# dm646x_cslr_uart register map
Vendor: Texas Instruments
Peripheral module from a debugger description file.
Registers are 32-bit, access not given, reset 0x0 unless marked. A register's access mark holds for its fields unless they carry their own. Offsets are as the file gives them; lines under a group give offsets from that group; [hi:lo] are bit positions; {n}, {i} and the like mark numbered series; 'fields as' and 'values as' point back to an identical list; <NAME> marks a mode.

## UART — UART/IrDA/CIR
0x00 RHR — Receive Holding Register
  [7:0] RHR ro
0x00 THR — Transmit Holding Register
  [7:0] THR wo
0x00 DLL — Divisor Latches Low
  [7:0] CLOCK_LSB rw — LSB divisor value
0x04 IER — Interrupt Enable Register
  [7] CTS_IT rw — UART MODE ONLY, 0 disables CTS interrupt
  [7] EOF_IT rw — IRDA MODE ONLY, 0 disables received EOF interrupt
  [6] LINE_STS_IT_IRDA rw — IRDA MODE ONLY, 0 disables receiver line status interrupt
  [6] RTS_IT rw — UART MODE ONLY, 0 disables RTS interrupt
  [5] XOFF_IT rw — UART MODE ONLY, 0 disables XOFF interrupt
  [5] TX_STATUS_IT rw — IRDA and CIR MODE ONLY, 0 disables TX status interrupt
  [4] STS_FIFO_TRIG_IT rw — IRDA MODE ONLY, 0 disables FIFO trigger level interrupt
  [4] SLEEP_MODE rw — UART MODE ONLY, 0 disables sleep mode
  [3] MODEM_STS_IT rw — UART MODE ONLY, 0 disables modem status interrupt
  [3] RX_OVERRUN_IT rw — IRDA and CIR MODE ONLY, 0 disables RX overrun interrupt
  [2] LAST_RX_BYTE_IT rw — IRDA MODE ONLY, 0 disables last byte of frame in RX FIFO interrupt
  [2] LINE_STS_IT_UART rw — UART MODE ONLY, 0 disables receiver line status interrupt
  [2] RX_STOP_IT rw — CIR MODE ONLY, 0 disables receive stop interrupt
  [1] THR_IT rw — 0 disables THR interrupt
  [0] RHR_IT rw — 0 disables RHR interrupt
0x04 DLH — Divisor Latches High
  [5:0] CLOCK_MSB rw — MSB divisor value
0x08 IIR reset 0x1 — Interrupt Identification Register
  [7] EOF_IT ro — IRDA MODE ONLY, 1 means received EOF interrupt active
  [7:6] FCR_MIRROR ro — UART MODE ONLY, Mirror the contents of FCR[0] on both bits
  [6] LINE_STS_IT ro — IRDA MODE ONLY, 1 means receiver line status interrupt active
  [5] TX_STATUS_IT ro — IRDA and CIR MODE ONLY, 1 means TX status interrupt active
  [4] STS_FIFO_IT ro — IRDA MODE ONLY, 1 means status FIFO trigger level interrupt active
  [3] RX_OE_IT ro — IRDA and CIR MODE ONLY, 1 means RX overrun interrupt active
  [2] RX_FIFO_LAST_BYTE_IT ro — IRDA MODE ONLY, 1 means last byte of frame in RX FIFO interrupt active
  [2] RX_STOP_IT ro — CIR MODE ONLY, 1 means receive stop interrupt active
  [5:1] IT_TYPE ro — UART MODE ONLY, Interrupt type identification
  [1] THR_IT ro — IRDA and CIR MODE ONLY, 1 means active THR interrupt
  [0] IT_PENDING ro — UART MODE ONLY, 1 means no pending interrupt
  [0] RHR_IT ro — IRDA and CIR MODE ONLY, 1 means active RHR interrupt
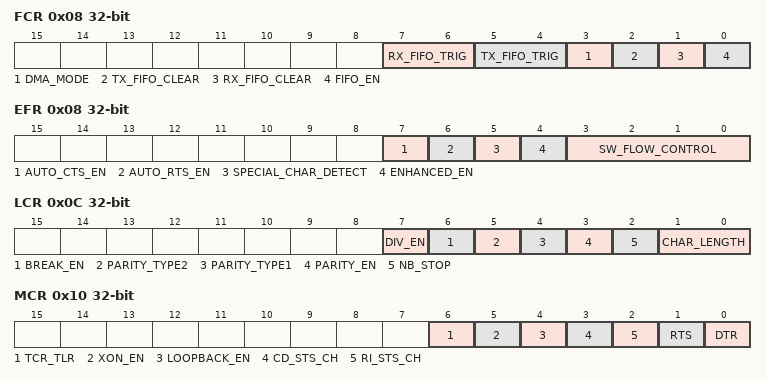
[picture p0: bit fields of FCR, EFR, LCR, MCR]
0x08 FCR — FIFO Control Register
  [7:6] RX_FIFO_TRIG wo — Set trigger elvel for RX FIFO
  [5:4] TX_FIFO_TRIG wo — Set trigger level for TX FIFO
  [3] DMA_MODE wo — 1 means DMA mode 1, 0 means no DMA
  [2] TX_FIFO_CLEAR wo — 1 clears transmit FIFO
  [1] RX_FIFO_CLEAR wo — 1 clears receive FIFO
  [0] FIFO_EN wo — 1 enables FIFO
0x08 EFR — Enhanced Feature Register
  [7] AUTO_CTS_EN rw — Auto-CTS enable
  [6] AUTO_RTS_EN rw — Auto-RTS enable
  [5] SPECIAL_CHAR_DETECT rw — Special character detect enable
  [4] ENHANCED_EN rw — Enhanced functions write enable bit
  [3:0] SW_FLOW_CONTROL rw — Defines software flow control
0x0C LCR — Line Control Register
  [7] DIV_EN rw — 1 enables divisor latch
  [6] BREAK_EN rw — Break control bit
  [5] PARITY_TYPE2 rw — Select forced parity format
  [4] PARITY_TYPE1 rw — 0->odd parity; 1->even parity
  [3] PARITY_EN rw — Enable parity bit generation
  [2] NB_STOP rw — Specifies number of stop bits
  [1:0] CHAR_LENGTH rw — Specifies word length
0x10 MCR — Modem Control Register
  [6] TCR_TLR rw — 1 enables access to TCR and TLR
  [5] XON_EN rw — 1 enables 'XON any'function
  [4] LOOPBACK_EN rw — 1 enables internal local loopback mode
  [3] CD_STS_CH rw — 1 in loopback forces DCD input low and IRQ output inactive
  [2] RI_STS_CH rw — 1 in loopback forces RI input low
  [1] RTS rw — 1 forces RTS output to active
  [0] DTR rw — 1 forces DTR output to active
0x10 XON1_ADDR1
  [7:0] XON_WORD1 rw — Store the 8-bit XON1 character in UART mode and ADDR1 address 1 for IRDA mode
0x14 LSR reset 0xE2 — Line Status Register
  [7] RX_FIFO_STS ro — UART MODE ONLY, 1 means there is at least one remaining error
  [7] THR_EMPTY ro — IRDA and CIR MODE ONLY, I means TX FIFO is empty
  [6] STS_FIFO_FULL ro — IRDA MODE ONLY, 1 means status FIFO full
  [6] TX_SR_E ro — UART MODE ONLY, 1 means TX FIFO and shift registers are empty
  [5] TX_FIFO_E ro — UART MODE ONLY, 1 means TX FIFO is empty
  [5] RX_LAST_BYTE ro — IRDA MODE ONLY, I means last byte in the frame
  [5] RX_STOP ro — CIR MODE ONLY, 1 means reception is completed
  [4] RX_BI ro — UART MODE ONLY, 1 means break
  [4] FRAME_TOO_LONG ro — IRDA MODE ONLY, 1 means frame is too long
  [3] ABORT ro — IRDA MODE ONLY, I means abort pattern is received
  [3] RX_FE ro — UART MODE ONLY, 1 means framing error in data being read from RX FIFO
  [2] RX_PE ro — UART MODE ONLY, 1 means parity error in data being read from RX FIFO
  [2] CRC ro — IRDA MODE ONLY, 1 means CRC error
  [1] STS_FIFO_E ro — IRDA MODE ONLY, 1 means status FIFO empty
  [1] RX_OE ro — UART MODE ONLY, 1 means overrun error
  [0] RX_FIFO_E ro — 1 means at least on data in RX FIFO in UART MODE; 0 means so in IRDA and CIR MODE
0x14 XON2_ADDR2
  [7:0] XON_WORD2 rw — Store the 8-bit XON2 character in UART mode and ADDR2 address 1 for IRDA mode
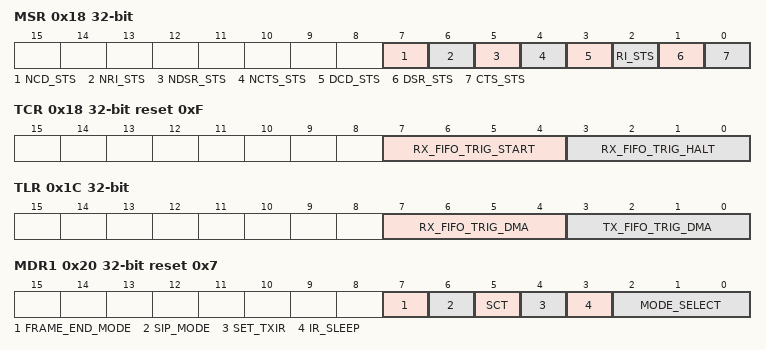
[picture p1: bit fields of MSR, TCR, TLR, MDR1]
0x18 MSR — Modem Status Register
  [7] NCD_STS ro — complement of DCD_STS
    1=DCTS
  [6] NRI_STS ro — complement of RI_STS
    1=DDSR; 0=NODDSR
  [5] NDSR_STS ro — complement of DSR_STS
    1=TERI; 0=NOTERI
  [4] NCTS_STS ro — complement of CTS_STS
    1=DCD; 0=NODCD
  [3] DCD_STS ro — 1 indicates DCD input has changed state
    1=CTS; 0=NOCTS
  [2] RI_STS ro — 1 indicates RI input has changed state
    1=DSR; 0=NODSR
  [1] DSR_STS ro — 1 indicates DSR input has changed state
    1=RI; 0=NORI
  [0] CTS_STS ro — 1 indicates CTS input has changed state
    1=CD; 0=NOCD
0x18 TCR reset 0xF — Transmission Control Register
  [7:4] RX_FIFO_TRIG_START rw — RX FIFO trigger to restore transmission
  [3:0] RX_FIFO_TRIG_HALT rw — RX FIFO trigger to halt transmission
0x18 XOFF1
  [7:0] XOFF_WORD1 rw — Store 8 bit XOFF1 character
0x1C SPR — Scratchpad Register
  [7:0] SPR_WORD rw — Scratchpad register
0x1C TLR — Trigger Level Register
  [7:4] RX_FIFO_TRIG_DMA rw — Receive FIFO trigger level
  [3:0] TX_FIFO_TRIG_DMA rw — Transmit FIFO trigger level
0x1C XOFF2
  [7:0] XOFF_WORD2 rw — Store 8 bit XOFF2 character
0x20 MDR1 reset 0x7 — Mode Definition Register 1
  [7] FRAME_END_MODE rw — IRDA MODE ONLY, chooses frame end mode
  [6] SIP_MODE rw — 1 for automatic SIP mode for MIR/FIR mode
  [5] SCT rw — Store and control the transmission
  [4] SET_TXIR rw — 1 forces IRTX pin output high
  [3] IR_SLEEP rw — 1 enalbes IRDA/CIR sleep mode
  [2:0] MODE_SELECT rw
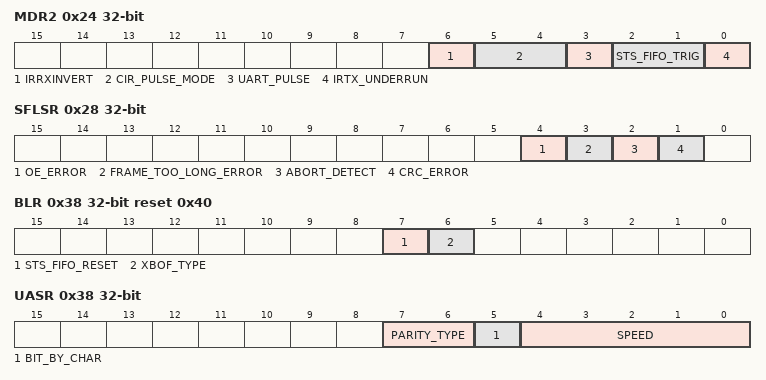
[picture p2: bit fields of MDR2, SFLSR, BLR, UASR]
0x24 MDR2 — Mode Definition Register 2
  [6] IRRXINVERT rw — IRDA and CIR MODE Only, invert RX pin inside the module
  [5:4] CIR_PULSE_MODE rw — CIR pulse modulatino definition
  [3] UART_PULSE rw — UART MODE ONLY, 1 allow pulse shaping in UART mode
  [2:1] STS_FIFO_TRIG rw — IRDA MODE ONLY, for framd ststus FIFO threshold
  [0] IRTX_UNDERRUN ro — IRDA transmission status interrupt
0x28 SFLSR — Status FIFO Line Status Register
  [4] OE_ERROR ro — 1: Overrun error
  [3] FRAME_TOO_LONG_ERROR ro — 1: Frame-length too long error
  [2] ABORT_DETECT ro — 1: Abort pattern
  [1] CRC_ERROR ro — 1: CRC error
0x28 TXFLL — Transmit Frame Length Low
  [7:0] TXFLL wo — LSB register to specify the frame length
0x2C RESUME
  [7:0] RESUME ro — Dummy read to start TX or RX
0x2C TXFLH — Transmit Frame Length High
  [4:0] TXFLL wo — MSB register to specify the frame length
0x30 SFREGL — Status FIFO Low
  [7:0] SFREGL ro — LSB part of the frame length
0x30 RXFLL — Receive Frame Length Low
  [7:0] RXFLL wo — LSB part of the frame length
0x34 SFREGH — Status FIFO High
  [3:0] SFREGH ro — MSB part of the frame length
0x34 RXFLH — Receive Frame Length High
  [3:0] RXFLH wo — MSB part of the frame length
0x38 BLR reset 0x40 — BOF Control Register
  [7] STS_FIFO_RESET rw — Status FIFO reset (self clearing bit)
  [6] XBOF_TYPE rw — SIR xBOF select
0x38 UASR — Autobauding Status Register
  [7:6] PARITY_TYPE ro — Used to report partiy type identified
  [5] BIT_BY_CHAR ro — Used to report 7-bit character or 8-bit character identified
  [4:0] SPEED ro — Used to report identified speed
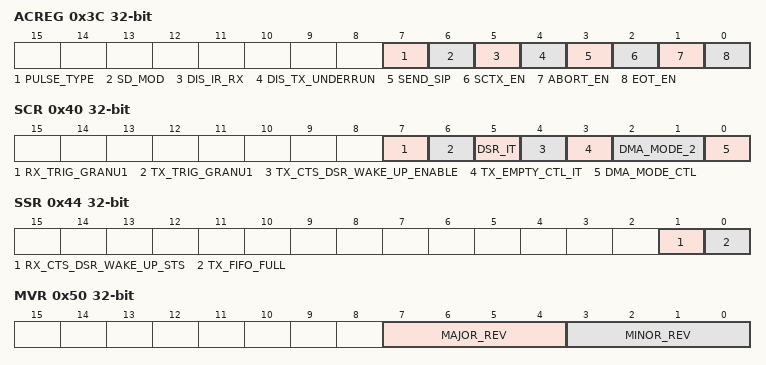
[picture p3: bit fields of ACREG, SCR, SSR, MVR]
0x3C ACREG — Auxiliary Control Register
  [7] PULSE_TYPE rw — SIR pulse width select
  [6] SD_MOD rw — Primary output used to configure transceivers
  [5] DIS_IR_RX rw — 1 disables RX input permanently
  [4] DIS_TX_UNDERRUN rw — 1 to transmit long stop bits
  [3] SEND_SIP rw — 1 send serial infrared interaction pulse in FIR/MIR mode
  [2] SCTX_EN rw — Store and controlled TX start
  [1] ABORT_EN rw — Frame abort
  [0] EOT_EN rw — End of transmission
0x40 SCR — Supplementary Control Register
  [7] RX_TRIG_GRANU1 rw — 1 enables the granularity of 1 for trigger RX level
  [6] TX_TRIG_GRANU1 rw — 1 enables the granularity of 1 for trigger TX level
  [5] DSR_IT rw — 1 enables DSR interrupt
  [4] TX_CTS_DSR_WAKE_UP_ENABLE rw — 1: wait for a faling edge of pins RX, CTS, or DSR, to generate an interrupt
  [3] TX_EMPTY_CTL_IT rw — THR interrupt setup
  [2:1] DMA_MODE_2 rw — Specify DMA mode
  [0] DMA_MODE_CTL rw — Set DMA mode
0x44 SSR — Supplementary Status Register
  [1] RX_CTS_DSR_WAKE_UP_STS ro — 1: a falling edge occurred on RX, CTS, or DSR
  [0] TX_FIFO_FULL ro — 1: TX FIFO is full
0x48 EBLR — BOF Length Register
  [7:0] EBLR rw — BOF length register
0x50 MVR — Module Version Register
  [7:4] MAJOR_REV ro — Major revision number of the module
  [3:0] MINOR_REV ro — Minor revision number of the module
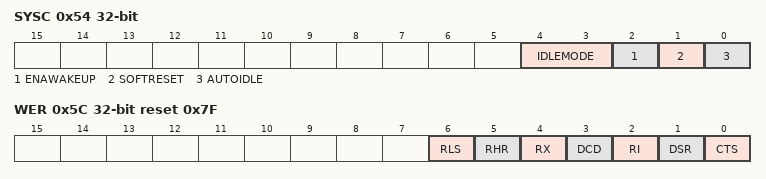
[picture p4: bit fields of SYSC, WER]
0x54 SYSC — System Configuration Register
  [4:3] IDLEMODE rw — Power management REQ/ACK control
  [2] ENAWAKEUP rw — Wake up feature control
  [1] SOFTRESET rw — Software reset
  [0] AUTOIDLE rw — Internal OCP clock gating strategy
0x58 SYSS — System Status Register
  [0] RESETDONE ro — Internal Reset Monitoring
0x5C WER reset 0x7F — Wake-Up Enable Register
  [6] RLS rw — Receiver line status interrupt can wake up the system
  [5] RHR rw — RHR interrupt can wake up the system
  [4] RX rw — RX event can wake up the system
  [3] DCD rw — DCD event can wake up the system
  [2] RI rw — RI event can wake up the system
  [1] DSR rw — DSR event can wake up the system
  [0] CTS rw — CTS event can wake up the system
0x60 CFPS reset 0x69 — Carrier Frequency Prescaler
  [7:0] CFPS rw — System clock frequency prescaler
